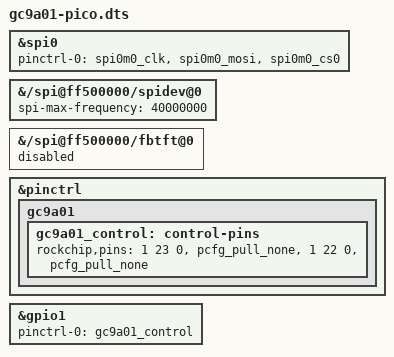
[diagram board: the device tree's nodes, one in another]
/dts-v1/;
/plugin/;

// 标准 Luckfox Pico：物理脚 12/14/15 = SPI0 CS0/CLK/MOSI。
// 复用 SDK luckfox-config 的 pinctrl 和 spidev 节点，MISO 不接。
&spi0 {
    status = "okay";
    pinctrl-0 = <&spi0m0_clk &spi0m0_mosi &spi0m0_cs0>;
};
&{/spi@ff500000/spidev@0} {
    status = "okay";
    spi-max-frequency = <40000000>;
};
&{/spi@ff500000/fbtft@0} {
    status = "disabled";
};

// DC/RST 使用 GPIO1_C7/C6。显式设置 GPIO 复用，不依赖引导时寄存器状态。
&pinctrl {
    gc9a01 {
        gc9a01_control: control-pins {
            rockchip,pins = <1 23 0 &pcfg_pull_none>, <1 22 0 &pcfg_pull_none>;
        };
    };
};
&gpio1 {
    pinctrl-names = "default";
    pinctrl-0 = <&gc9a01_control>;
};
